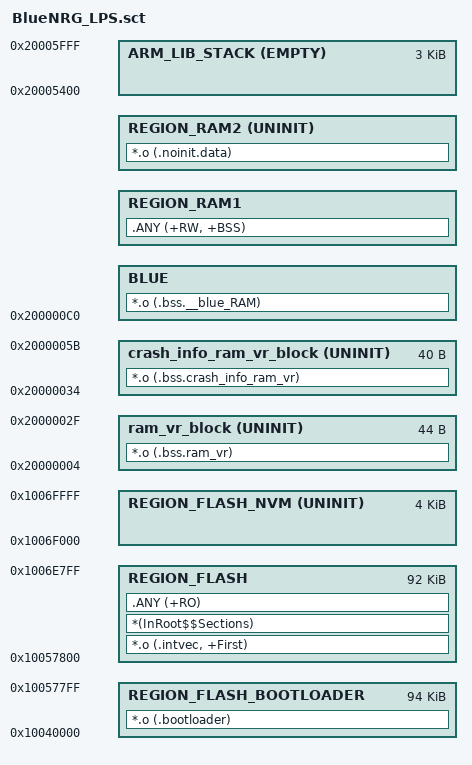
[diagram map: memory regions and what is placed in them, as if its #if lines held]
#!armclang -E --target=arm-arm-none-eabi -mcpu=cortex-m0plus -xc
/*******************************************************************************
* BlueNRG-LPS generic linker file for KEIL
* Main linker variables to control it are:
*
* MEMORY_FLASH_APP_SIZE: define the size of the application in case not all the flash is needed.
* Default value is: 188KB when no OTA firmware upgrade is supported
*
* MEMORY_FLASH_APP_OFFSET: define the offset of the application.
* Default value is: 0 offset
*
* MEMORY_RAM_APP_OFFSET: define the offset in RAM from which variables can be
* allocated.
* 
* CONFIG_OTA_HIGHER: When defined application is built for OTA support
* in the higher part of memory
*
* CONFIG_OTA_LOWER: When defined application is built for OTA support
* in the lower part of memory
*
* CONFIG_OTA_USE_SERVICE_MANAGER: When defined application is built for
* OTA firmware upgrade support with separated application for firmware upgrade
*
*******************************************************************************/

/*******************************************************************************
* Memory Definitions
*******************************************************************************/
/*
BlueNRG-LPS memory map
+-----------------------+ 0x20005FFF
|  RAM (24K)            |
+-----------------------+ 0x20000000
|                       |
|                       |
+-----------------------+ 0x1006FFFF
|                       |
|  FLASH (192K)         |
+-----------------------+ 0x10040000
|                       |
+-----------------------| 0x100017FF
|   ROM (6K)            |
+-----------------------+ 0x10000000
*/

#define _MEMORY_RAM_BEGIN_    0x20000000 
#define _MEMORY_RAM_SIZE_     0x10000         /* 24KB  */
#define _MEMORY_RAM_END_      0x20005FFF 

#define _MEMORY_FLASH_BEGIN_  0x10040000  
#define _MEMORY_FLASH_SIZE_   0x30000          /* 192KB */ 
#define _MEMORY_FLASH_END_    0x1006FFFF  

#define _MEMORY_ROM_BEGIN_    0x10000000    
#define _MEMORY_ROM_SIZE_     0x1800           /* 6KB */ 
#define _MEMORY_ROM_END_      0x10001FFF  


/* Reserved for BTLE stack non volatile memory */
#define FLASH_NVM_DATASIZE     (4*1024)


#ifdef CONFIG_OTA_HIGHER
  /* This configuration is intended for application supporting OTA firmware upgrade with 2-app scheme (app in the upper part of memory map) */
  /*
     BlueNRG-LPS OTA firmware upgrade support for higher application memory map
     +-----------------------+ 0x20005FFF
     |  RAM (24K)            |
     +-----------------------+ 0x20000000
     |                       |
     |                       |
     +-----------------------+ 0x10070000
     |  NVM(4K)              |
     +-----------------------+ 0x1006F000
     +-----------------------+ 0x1006E800
     |                       |
     |  Higher app (92K)     |
     +-----------------------+ 0x10057800
     |                       |
     |  Lower app (92K)      |
     +-----------------------| 0x10040800
     |  Reset Manager (2K)   |
     +-----------------------+ 0x10040000
     |                       |
     +-----------------------| 0x100017FF
     |   ROM (6K)            |
     +-----------------------+ 0x10000000
  */

#ifndef RESET_MANAGER_SIZE
#define RESET_MANAGER_SIZE     (0x800)
#endif 

/* Divide remaining space by 2 and round to the sector boundary. */
#define MEMORY_FLASH_APP_SIZE  (((_MEMORY_FLASH_SIZE_ - RESET_MANAGER_SIZE - FLASH_NVM_DATASIZE)/2)/2048)*2048
#define MEMORY_FLASH_APP_OFFSET  (RESET_MANAGER_SIZE + MEMORY_FLASH_APP_SIZE)

#else
#ifdef CONFIG_OTA_LOWER
  /* This configuration is intended for application supporting OTA firmware upgrade with 2-app scheme (app in the lower part of memory map) */
  /*
     BlueNRG-LPS OTA firmware upgrade support for lower application memory map
     +-----------------------+ 0x20005FFF
     |  RAM (24K)            |
     +-----------------------+ 0x20000000
     |                       |
     |                       |
     +-----------------------+ 0x10070000
     |  NVM(4K)              |
     +-----------------------+ 0x1006F000
     +-----------------------+ 0x1006E800
     |                       |
     |  Higher app (92K)     |
     +-----------------------+ 0x10057800
     |                       |
     |  Lower app (92K)      |
     +-----------------------| 0x10040800
     |  Reset Manager (2K)   |
     +-----------------------+ 0x10040000
     |                       |
     +-----------------------| 0x100017FF
     |   ROM (6K)            |
     +-----------------------+ 0x10000000
  */

#ifndef RESET_MANAGER_SIZE
#define RESET_MANAGER_SIZE     (0x800)
#endif 

#define MEMORY_FLASH_APP_SIZE  (((_MEMORY_FLASH_SIZE_ - RESET_MANAGER_SIZE - FLASH_NVM_DATASIZE)/2)/2048)*2048
#define MEMORY_FLASH_APP_OFFSET  (RESET_MANAGER_SIZE)

#else
#ifdef CONFIG_OTA_USE_SERVICE_MANAGER
  /* This configuration is intended for application supporting OTA firmware upgrade with independent OTA firmware upgrade service manager
  (app in the upper part of memory map) */
  /*
     BlueNRG-LPS OTA firmware upgrade support for service manager application memory map
     +-----------------------+ 0x20005FFF
     |  RAM (24K)            |
     +-----------------------+ 0x20000000
     |                       |
     |                       |
     +-----------------------+ 0x10070000
     |                       |
     |  NVM(4K)              |
     +-----------------------+ 0x1006F000
     |                       |
     |  User app (94K)       |
     +-----------------------+ 0x10057800
     |  OTA Service          |
     |  Manager (94K)        |
     +-----------------------+ 0x10040000
     |                       |
     +-----------------------| 0x100017FF
     |   ROM (6K)            |
     +-----------------------+ 0x10000000
  */

 /* Including OTA firmware upgrade service manager application */
#define SERVICE_MANAGER_SIZE     (0x17800)

#define MEMORY_FLASH_APP_SIZE  (_MEMORY_FLASH_SIZE_ - SERVICE_MANAGER_SIZE - FLASH_NVM_DATASIZE)
#define MEMORY_FLASH_APP_OFFSET  (SERVICE_MANAGER_SIZE)

#else
  /* This configuration is intended for application not supporting OTA firmware upgrade */
  /*
  BlueNRG-LPS standard application memory map
  +-----------------------+ 0x20005FFF
  |  RAM (24K)            |
  +-----------------------+ 0x20000000
  |                       |
  |                       |
  +-----------------------+ 0x10070000
  |                       |
  |  NVM(4K)              |
  +-----------------------+ 0x1006F000
  |                       |
  |  User app (188K)      |
  +-----------------------+ 0x10040000
  |                       |
  +-----------------------| 0x100017FF
  |   ROM (6K)            |
  +-----------------------+ 0x10000000
*/

#ifndef MEMORY_FLASH_APP_OFFSET
#define MEMORY_FLASH_APP_OFFSET  (0)
#endif

#ifndef MEMORY_FLASH_APP_SIZE
#define MEMORY_FLASH_APP_SIZE  (_MEMORY_FLASH_SIZE_ - FLASH_NVM_DATASIZE - MEMORY_FLASH_APP_OFFSET)
#endif

#endif
#endif
#endif


LR_IROM2 (_MEMORY_FLASH_BEGIN_) MEMORY_FLASH_APP_OFFSET  {    ; load region size_region
  REGION_FLASH_BOOTLOADER (_MEMORY_FLASH_BEGIN_) (MEMORY_FLASH_APP_OFFSET)  {  ; load address = execution address
   *.o (.bootloader)
  }
}
  
LR_IROM1 (_MEMORY_FLASH_BEGIN_+MEMORY_FLASH_APP_OFFSET) _MEMORY_FLASH_SIZE_  {    ; load region size_region
  REGION_FLASH (_MEMORY_FLASH_BEGIN_ + MEMORY_FLASH_APP_OFFSET) (MEMORY_FLASH_APP_SIZE)  {  ; load address = execution address
   *.o (.intvec, +First)
   *(InRoot$$Sections)
   .ANY (+RO)
  }
  REGION_FLASH_NVM (_MEMORY_FLASH_END_- FLASH_NVM_DATASIZE + 1) UNINIT FLASH_NVM_DATASIZE  {
  }
  ram_vr_block 0x20000004 UNINIT 0x2C {
   *.o (.bss.ram_vr)
  }
  crash_info_ram_vr_block 0x20000034 UNINIT 40 {  
  *.o (.bss.crash_info_ram_vr)
  }
  BLUE 0x200000C0 {
  *.o (.bss.__blue_RAM)
  }
  
#ifndef MEMORY_RAM_APP_OFFSET
  REGION_RAM1 +0  {  ; RW data
   .ANY (+RW, +BSS)
  }
#else
  REGION_RAM1 (_MEMORY_RAM_BEGIN_ + MEMORY_RAM_APP_OFFSET) {  ; RW data
   .ANY (+RW, +BSS)
  }
#endif
  REGION_RAM2 +0 UNINIT  {  ; RW data not initialized
   *.o (.noinit.data)
  }
  ARM_LIB_STACK (_MEMORY_RAM_END_+1) EMPTY -0xC00 { }
}
